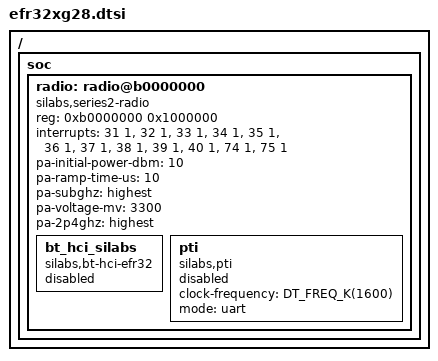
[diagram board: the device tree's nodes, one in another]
/*
 * Copyright (c) 2025 Silicon Laboratories Inc.
 *
 * SPDX-License-Identifier: Apache-2.0
 */

#include <silabs/xg28/xg28.dtsi>

/ {
	soc {
		radio: radio@b0000000 {
			compatible = "silabs,series2-radio";
			reg = <0xb0000000 0x1000000>;
			interrupts = <31 1>, <32 1>, <33 1>, <34 1>, <35 1>, <36 1>,
				     <37 1>, <38 1>, <39 1>, <40 1>, <74 1>, <75 1>;
			interrupt-names = "agc", "bufc", "frc_pri", "frc", "modem", "protimer",
					  "rac_rsm", "rac_seq", "hostmailbox", "synth",
					  "rfeca0", "rfeca1";
			pa-initial-power-dbm = <10>;
			pa-ramp-time-us = <10>;
			pa-subghz = "highest";
			pa-voltage-mv = <3300>;
			pa-2p4ghz = "highest";

			bt_hci_silabs: bt_hci_silabs {
				compatible = "silabs,bt-hci-efr32";
				status = "disabled";
			};

			pti: pti {
				compatible = "silabs,pti";
				clock-frequency = <DT_FREQ_K(1600)>;
				mode = "uart";
				status = "disabled";
			};
		};
	};
};
